# STM32H757_CM7 register map
File version: 1.3
CPU: CM7 r0p1, little endian, MPU, FPU, 4 interrupt priority bits
Registers are 32-bit, read-write, reset 0x0 unless marked. A register's access mark holds for its fields unless they carry their own. Offsets are from the block's base; [hi:lo] are bit positions; {n}, {i} and the like mark numbered series; 'fields as' and 'values as' point back to an identical list.

## DSIHOST — MIPI DSI Host
Base 0x50000000
0x00 VR ro reset 0x3133302A — DSI Host version register
  [31:0] VERSION — Version of the DSI Host
0x04 CR access not given — DSI Host control register
  [0] EN — Enable
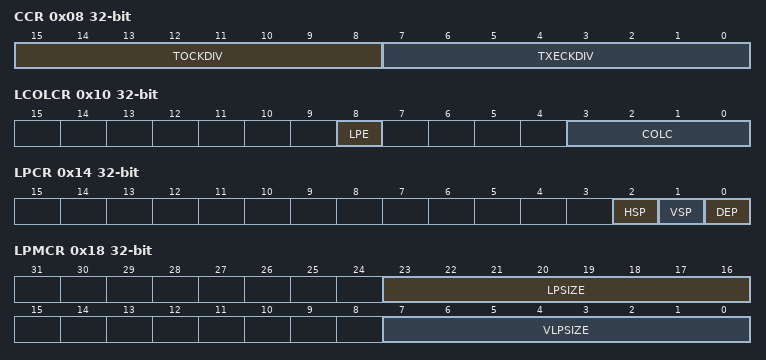
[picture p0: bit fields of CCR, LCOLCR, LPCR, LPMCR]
0x08 CCR access not given — DSI Host clock control register
  [15:8] TOCKDIV — Timeout clock division
  [7:0] TXECKDIV — TX escape clock division
0x0C LVCIDR access not given — DSI Host LTDC VCID register
  [1:0] VCID — Virtual channel ID
0x10 LCOLCR access not given — DSI Host LTDC color coding register
  [8] LPE — Loosely packet enable
  [3:0] COLC — Color coding
0x14 LPCR access not given — DSI Host LTDC polarity configuration register
  [2] HSP — HSYNC polarity
  [1] VSP — VSYNC polarity
  [0] DEP — Data enable polarity
0x18 LPMCR access not given — DSI Host low-power mode configuration register
  [23:16] LPSIZE — Largest packet size
  [7:0] VLPSIZE — VACT largest packet size
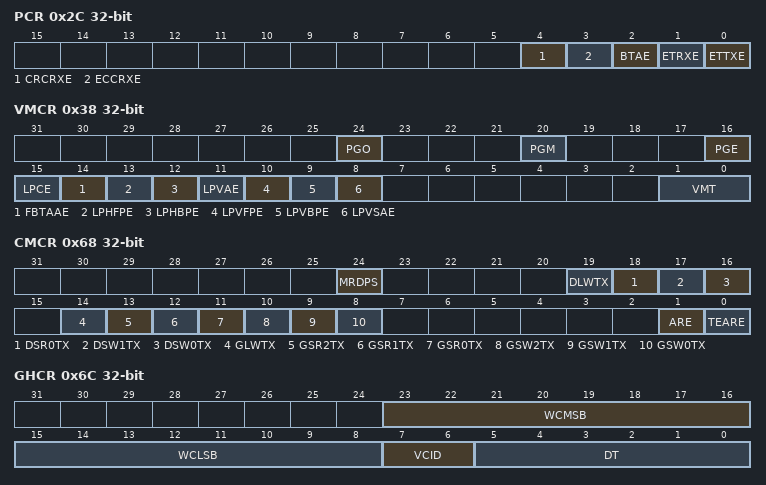
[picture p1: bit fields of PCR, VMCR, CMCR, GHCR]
0x2C PCR access not given — DSI Host protocol configuration register
  [4] CRCRXE — CRC reception enable
  [3] ECCRXE — ECC reception enable
  [2] BTAE — Bus
  [1] ETRXE — EoTp reception enable
  [0] ETTXE — EoTp transmission enable
0x30 GVCIDR access not given — DSI Host generic VCID register
  [1:0] VCID — Virtual channel ID
0x34 MCR access not given reset 0x1 — DSI Host mode configuration register
  [0] CMDM — Command mode
0x38 VMCR access not given — DSI Host video mode configuration register
  [24] PGO — Pattern generator orientation
  [20] PGM — Pattern generator mode
  [16] PGE — Pattern generator enable
  [15] LPCE — Low-power command enable
  [14] FBTAAE — Frame bus-turn-around acknowledge enable
  [13] LPHFPE — Low-power horizontal front-porch enable
  [12] LPHBPE — Low-power horizontal back-porch enable
  [11] LPVAE — Low-power vertical active enable
  [10] LPVFPE — Low-power vertical front-porch enable
  [9] LPVBPE — Low-power vertical back-porch enable
  [8] LPVSAE — Low-power vertical sync active enable
  [1:0] VMT — Video mode type
0x3C VPCR access not given — DSI Host video packet configuration register
  [13:0] VPSIZE — Video packet size
0x40 VCCR access not given — DSI Host video chunks configuration register
  [12:0] NUMC — Number of chunks
0x44 VNPCR access not given — DSI Host video null packet configuration register
  [12:0] NPSIZE — Null packet size
0x48 VHSACR access not given — DSI Host video HSA configuration register
  [11:0] HSA — Horizontal synchronism active duration
0x4C VHBPCR access not given — DSI Host video HBP configuration register
  [11:0] HBP — Horizontal back-porch duration
0x50 VLCR access not given — DSI Host video line configuration register
  [14:0] HLINE — Horizontal line duration
0x54 VVSACR access not given — DSI Host video VSA configuration register
  [9:0] VSA — Vertical synchronism active duration
0x58 VVBPCR access not given — DSI Host video VBP configuration register
  [9:0] VBP — Vertical back-porch duration
0x5C VVFPCR access not given — DSI Host video VFP configuration register
  [9:0] VFP — Vertical front-porch duration
0x60 VVACR access not given — DSI Host video VA configuration register
  [13:0] VA — Vertical active duration
0x64 LCCR access not given — DSI Host LTDC command configuration register
  [15:0] CMDSIZE — Command size
0x68 CMCR access not given — DSI Host command mode configuration register
  [24] MRDPS — Maximum read packet size
  [19] DLWTX — DCS long write transmission
  [18] DSR0TX — DCS short read zero parameter transmission
  [17] DSW1TX — DCS short read one parameter transmission
  [16] DSW0TX — DCS short write zero parameter transmission
  [14] GLWTX — Generic long write transmission
  [13] GSR2TX — Generic short read two parameters transmission
  [12] GSR1TX — Generic short read one parameters transmission
  [11] GSR0TX — Generic short read zero parameters transmission
  [10] GSW2TX — Generic short write two parameters transmission
  [9] GSW1TX — Generic short write one parameters transmission
  [8] GSW0TX — Generic short write zero parameters transmission
  [1] ARE — Acknowledge request enable
  [0] TEARE — Tearing effect acknowledge request enable
0x6C GHCR access not given — DSI Host generic header configuration register
  [23:16] WCMSB — WordCount MSB
  [15:8] WCLSB — WordCount LSB
  [7:6] VCID — Channel
  [5:0] DT — Type
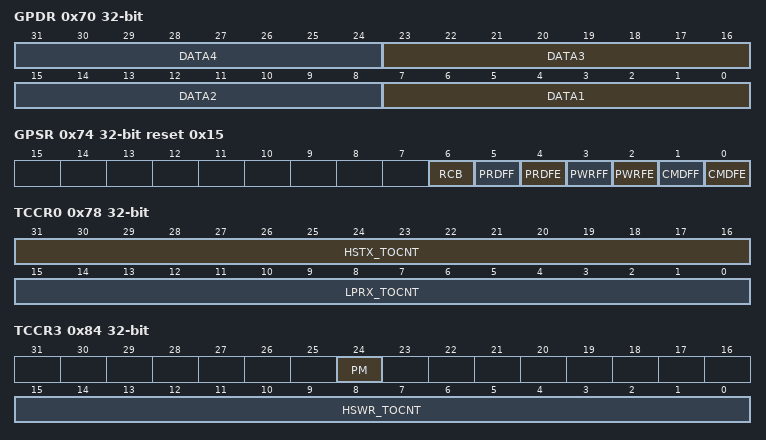
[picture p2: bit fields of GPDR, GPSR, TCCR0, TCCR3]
0x70 GPDR access not given — DSI Host generic payload data register
  [8n-1:8n-8] DATA{n} (n=1..4) — Payload byte {n}
0x74 GPSR access not given reset 0x15 — DSI Host generic packet status register
  [6] RCB — Read command busy
  [5] PRDFF — Payload read FIFO full
  [4] PRDFE — Payload read FIFO empty
  [3] PWRFF — Payload write FIFO full
  [2] PWRFE — Payload write FIFO empty
  [1] CMDFF — Command FIFO full
  [0] CMDFE — Command FIFO empty
0x78 TCCR0 access not given — DSI Host timeout counter configuration register 0
  [31:16] HSTX_TOCNT — High-speed transmission timeout counter
  [15:0] LPRX_TOCNT — Low-power reception timeout counter
0x7C TCCR1 access not given — DSI Host timeout counter configuration register 1
  [15:0] HSRD_TOCNT — High-speed read timeout counter
0x80 TCCR2 access not given — DSI Host timeout counter configuration register 2
  [15:0] LPRD_TOCNT — Low-power read timeout counter
0x84 TCCR3 access not given — DSI Host timeout counter configuration register 3
  [24] PM — Presp mode
  [15:0] HSWR_TOCNT — High-speed write timeout counter
0x88 TCCR4 access not given — DSI Host timeout counter configuration register 4
  [15:0] LPWR_TOCNT — Low-power write timeout counter
0x8C TCCR5 access not given — DSI Host timeout counter configuration register 5
  [15:0] BTA_TOCNT — Bus-turn-around timeout counter
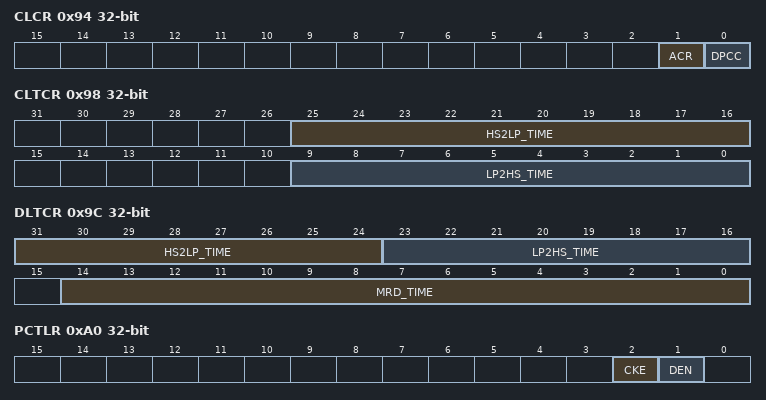
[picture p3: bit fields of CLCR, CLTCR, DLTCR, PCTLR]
0x94 CLCR access not given — DSI Host clock lane configuration register
  [1] ACR — Automatic clock lane control
  [0] DPCC — D-PHY clock control
0x98 CLTCR access not given — DSI Host clock lane timer configuration register
  [25:16] HS2LP_TIME — High-speed to low-power time
  [9:0] LP2HS_TIME — Low-power to high-speed time
0x9C DLTCR access not given — DSI Host data lane timer configuration register
  [31:24] HS2LP_TIME — High-speed to low-power time
  [23:16] LP2HS_TIME — Low-power to high-speed time
  [14:0] MRD_TIME — Maximum read time
0xA0 PCTLR access not given — DSI Host PHY control register
  [2] CKE — Clock enable
  [1] DEN — Digital enable
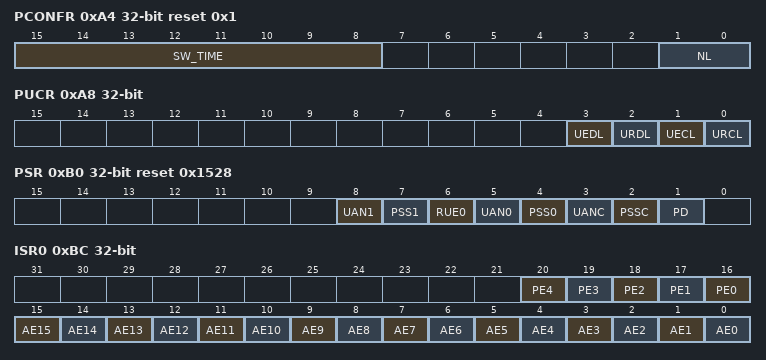
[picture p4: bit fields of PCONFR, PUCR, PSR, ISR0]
0xA4 PCONFR access not given reset 0x1 — DSI Host PHY configuration register
  [15:8] SW_TIME — Stop wait time
  [1:0] NL — Number of lanes
0xA8 PUCR access not given — DSI Host PHY ULPS control register
  [3] UEDL — ULPS exit on data lane
  [2] URDL — ULPS request on data lane
  [1] UECL — ULPS exit on clock lane
  [0] URCL — ULPS request on clock lane
0xAC PTTCR access not given — DSI Host PHY TX triggers configuration register
  [3:0] TX_TRIG — Transmission trigger
0xB0 PSR access not given reset 0x1528 — DSI Host PHY status register
  [8] UAN1 — ULPS active not lane 1
  [7] PSS1 — PHY stop state lane 1
  [6] RUE0 — RX ULPS escape lane 0
  [5] UAN0 — ULPS active not lane 1
  [4] PSS0 — PHY stop state lane 0
  [3] UANC — ULPS active not clock lane
  [2] PSSC — PHY stop state clock lane
  [1] PD — PHY direction
0xBC ISR0 access not given — DSI Host interrupt and status register 0
  [n+16] PE{n} (n=0..4) — PHY error {n}
  [n] AE{n} (n=0..15) — Acknowledge error {n}
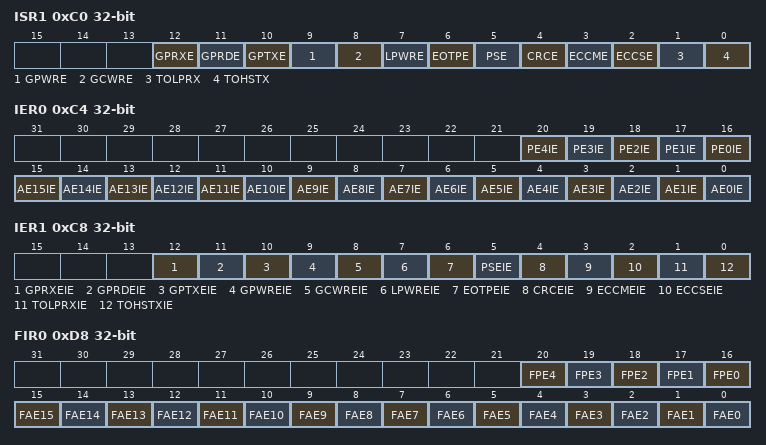
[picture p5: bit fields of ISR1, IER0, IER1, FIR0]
0xC0 ISR1 access not given — DSI Host interrupt and status register 1
  [12] GPRXE — Generic payload receive error
  [11] GPRDE — Generic payload read error
  [10] GPTXE — Generic payload transmit error
  [9] GPWRE — Generic payload write error
  [8] GCWRE — Generic command write error
  [7] LPWRE — LTDC payload write error
  [6] EOTPE — EoTp error
  [5] PSE — Packet size error
  [4] CRCE — CRC error
  [3] ECCME — ECC multi
  [2] ECCSE — ECC single
  [1] TOLPRX — Timeout low
  [0] TOHSTX — Timeout high
0xC4 IER0 access not given — DSI Host interrupt enable register 0
  [n+16] PE{n}IE (n=0..4) — PHY error {n} interrupt enable
  [n] AE{n}IE (n=0..15) — Acknowledge error {n} interrupt enable
0xC8 IER1 access not given — DSI Host interrupt enable register 1
  [12] GPRXEIE — Generic payload receive error interrupt enable
  [11] GPRDEIE — Generic payload read error interrupt enable
  [10] GPTXEIE — Generic payload transmit error interrupt enable
  [9] GPWREIE — Generic payload write error interrupt enable
  [8] GCWREIE — Generic command write error interrupt enable
  [7] LPWREIE — LTDC payload write error interrupt enable
  [6] EOTPEIE — EoTp error interrupt enable
  [5] PSEIE — Packet size error interrupt enable
  [4] CRCEIE — CRC error interrupt enable
  [3] ECCMEIE — ECC multi
  [2] ECCSEIE — ECC single
  [1] TOLPRXIE — Timeout low
  [0] TOHSTXIE — Timeout high
0xD8 FIR0 access not given — DSI Host force interrupt register 0
  [n+16] FPE{n} (n=0..4) — Force PHY error {n}
  [n] FAE{n} (n=0..15) — Force acknowledge error {n}
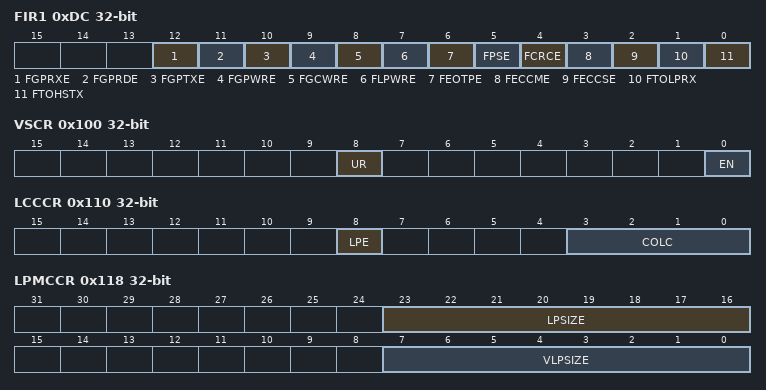
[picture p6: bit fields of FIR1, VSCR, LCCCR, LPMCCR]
0xDC FIR1 access not given — DSI Host force interrupt register 1
  [12] FGPRXE — Force generic payload receive error
  [11] FGPRDE — Force generic payload read error
  [10] FGPTXE — Force generic payload transmit error
  [9] FGPWRE — Force generic payload write error
  [8] FGCWRE — Force generic command write error
  [7] FLPWRE — Force LTDC payload write error
  [6] FEOTPE — Force EoTp error
  [5] FPSE — Force packet size error
  [4] FCRCE — Force CRC error
  [3] FECCME — Force ECC multi
  [2] FECCSE — Force ECC single
  [1] FTOLPRX — Force timeout low
  [0] FTOHSTX — Force timeout high
0x100 VSCR access not given — DSI Host video shadow control register
  [8] UR — Update register
  [0] EN — Enable
0x10C LCVCIDR access not given — DSI Host LTDC current VCID register
  [1:0] VCID — Virtual channel ID
0x110 LCCCR access not given — DSI Host LTDC current color coding register
  [8] LPE — Loosely packed enable
  [3:0] COLC — Color coding
0x118 LPMCCR access not given — DSI Host low-power mode current configuration register
  fields as LPMCR
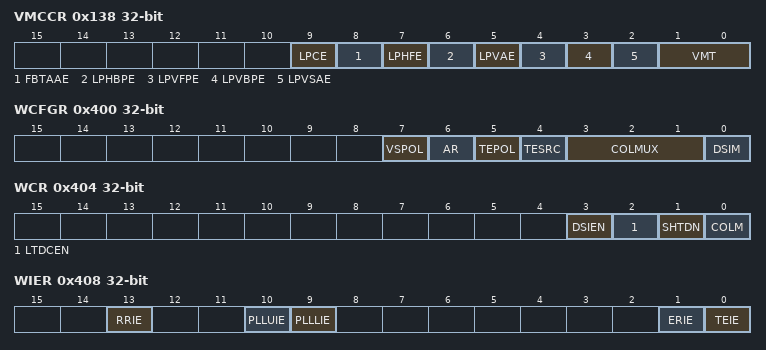
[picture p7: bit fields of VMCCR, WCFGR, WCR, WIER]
0x138 VMCCR access not given — DSI Host video mode current configuration register
  [9] LPCE — Low-power command enable
  [8] FBTAAE — Frame BTA acknowledge enable
  [7] LPHFE — Low-power horizontal front-porch enable
  [6] LPHBPE — Low-power horizontal back-porch enable
  [5] LPVAE — Low-power vertical active enable
  [4] LPVFPE — Low-power vertical front-porch enable
  [3] LPVBPE — Low-power vertical back-porch enable
  [2] LPVSAE — Low-power vertical sync time enable
  [1:0] VMT — Video mode type
0x13C VPCCR access not given — DSI Host video packet current configuration register
  [13:0] VPSIZE — Video packet size
0x140 VCCCR access not given — DSI Host video chunks current configuration register
  [12:0] NUMC — Number of chunks
0x144 VNPCCR access not given — DSI Host video null packet current configuration register
  [12:0] NPSIZE — Null packet size
0x148 VHSACCR access not given — DSI Host video HSA current configuration register
  [11:0] HSA — Horizontal synchronism active duration
0x14C VHBPCCR access not given — DSI Host video HBP current configuration register
  [11:0] HBP — Horizontal back
0x150 VLCCR access not given — DSI Host video line current configuration register
  [14:0] HLINE — Horizontal line duration
0x154 VVSACCR access not given — DSI Host video VSA current configuration register
  [9:0] VSA — Vertical synchronism active duration
0x158 VVPBCCR access not given — DSI Host video VBP current configuration register
  [9:0] VBP — Vertical back
0x15C VVFPCCR access not given — DSI Host video VFP current configuration register
  [9:0] VFP — Vertical front
0x160 VVACCR access not given — DSI Host video VA current configuration register
  [13:0] VA — Vertical active duration
0x400 WCFGR access not given — DSI wrapper configuration register
  [7] VSPOL — VSync polarity
  [6] AR — Automatic refresh
  [5] TEPOL — TE polarity
  [4] TESRC — TE source
  [3:1] COLMUX — Color multiplexing
  [0] DSIM — DSI mode
0x404 WCR access not given — DSI wrapper control register
  [3] DSIEN — DSI enable
  [2] LTDCEN — LTDC enable
  [1] SHTDN — Shutdown
  [0] COLM — Color mode
0x408 WIER access not given — DSI wrapper interrupt enable register
  [13] RRIE — Regulator ready interrupt enable
  [10] PLLUIE — PLL unlock interrupt enable
  [9] PLLLIE — PLL lock interrupt enable
  [1] ERIE — End of refresh interrupt enable
  [0] TEIE — Tearing effect interrupt enable
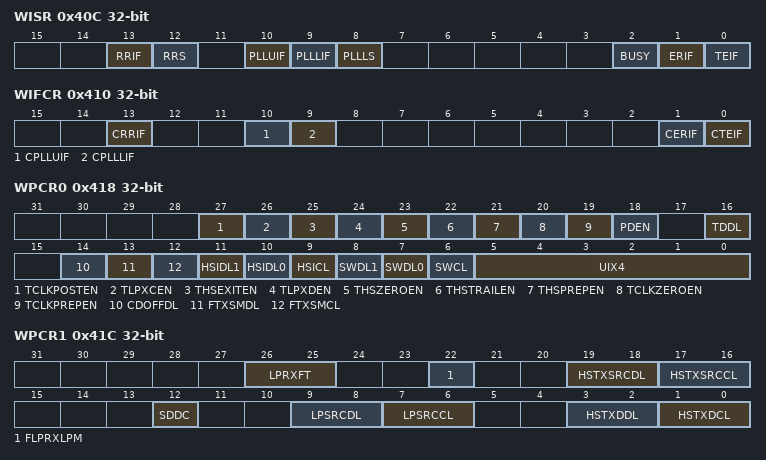
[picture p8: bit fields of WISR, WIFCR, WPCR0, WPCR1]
0x40C WISR access not given — DSI wrapper interrupt and status register
  [13] RRIF — Regulator ready interrupt flag
  [12] RRS — Regulator ready status
  [10] PLLUIF — PLL unlock interrupt flag
  [9] PLLLIF — PLL lock interrupt flag
  [8] PLLLS — PLL lock status
  [2] BUSY — Busy flag
  [1] ERIF — End of refresh interrupt flag
  [0] TEIF — Tearing effect interrupt flag
0x410 WIFCR access not given — DSI wrapper interrupt flag clear register
  [13] CRRIF — Clear regulator ready interrupt flag
  [10] CPLLUIF — Clear PLL unlock interrupt flag
  [9] CPLLLIF — Clear PLL lock interrupt flag
  [1] CERIF — Clear end of refresh interrupt flag
  [0] CTEIF — Clear tearing effect interrupt flag
0x418 WPCR0 access not given — DSI wrapper PHY configuration register 0
  [27] TCLKPOSTEN — Custom time for tCLK
  [26] TLPXCEN — Custom time for tLPX for clock lane enable
  [25] THSEXITEN — Custom time for tHS
  [24] TLPXDEN — Custom time for tLPX for data lanes enable
  [23] THSZEROEN — Custom time for tHS
  [22] THSTRAILEN — Custom time for tHS
  [21] THSPREPEN — Custom time for tHS
  [20] TCLKZEROEN — Custom time for tCLK
  [19] TCLKPREPEN — Custom time for tCLK
  [18] PDEN — Pull-down enable
  [16] TDDL — Turn disable data lanes
  [14] CDOFFDL — Contention detection OFF on data lanes
  [13] FTXSMDL — Force in TX Stop mode the data lanes
  [12] FTXSMCL — Force in TX Stop mode the clock lane
  [11] HSIDL1 — Invert the high-speed data signal on data lane 1
  [10] HSIDL0 — Invert the high-speed data signal on data lane 0
  [9] HSICL — Invert high
  [8] SWDL1 — Swap data lane 1 pins
  [7] SWDL0 — Swap data lane 0 pins
  [6] SWCL — Swap clock lane pins
  [5:0] UIX4 — Unit interval multiplied by 4
0x41C WPCR1 access not given — DSI wrapper PHY configuration register 1
  [26:25] LPRXFT — Low-power RX low-pass filtering tuning
  [22] FLPRXLPM — Forces LP receiver in low-power mode
  [19:18] HSTXSRCDL — High-speed transmission slew-rate control on data lanes
  [17:16] HSTXSRCCL — High-speed transmission slew-rate control on clock lane
  [12] SDDC — SDD control
  [9:8] LPSRCDL — Low-power transmission slew-rate compensation on data lanes
  [7:6] LPSRCCL — Low-power transmission slew-rate compensation on clock lane
  [3:2] HSTXDDL — High-speed transmission delay on data lanes
  [1:0] HSTXDCL — High-speed transmission delay on clock lane
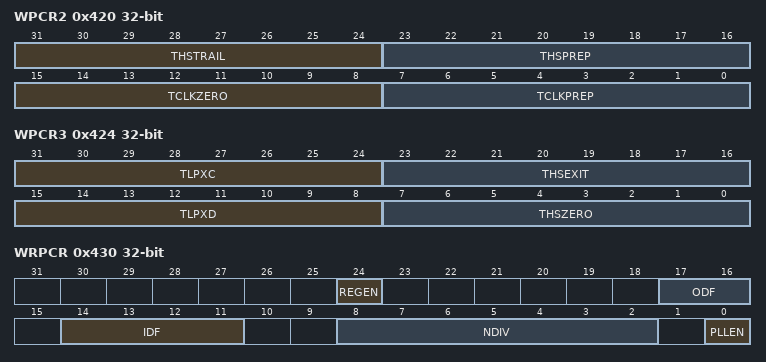
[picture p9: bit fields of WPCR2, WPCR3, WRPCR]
0x420 WPCR2 access not given — DSI wrapper PHY configuration register 2
  [31:24] THSTRAIL
  [23:16] THSPREP — tHS-PREPARE
  [15:8] TCLKZERO
  [7:0] TCLKPREP — tCLK-PREPARE
0x424 WPCR3 access not given — DSI wrapper PHY configuration register 3
  [31:24] TLPXC — tLPXC for clock lane
  [23:16] THSEXIT
  [15:8] TLPXD — tLPX for data lanes
  [7:0] THSZERO
0x428 WPCR4 access not given — DSI wrapper PHY configuration register 4
  [7:0] TCLKPOST
0x430 WRPCR access not given — DSI wrapper regulator and PLL control register
  [24] REGEN — Regulator enable
  [17:16] ODF — PLL output division factor
  [14:11] IDF — PLL input division factor
  [8:2] NDIV — PLL loop division factor
  [0] PLLEN — PLL enable
